# pwrseq_me14 register map
Registers are access not given, no defined reset value unless marked. A register's access mark holds for its fields unless they carry their own. Offsets are from the block's base; lines under a group give offsets from that group; [hi:lo] are bit positions; {n}, {i} and the like mark numbered series; 'fields as' and 'values as' point back to an identical list; <NAME> marks a mode.

## Memory map
0x40006800 PWRSEQ size 0x400 — Power Sequencer / Low Power Control Register.

## PWRSEQ — Power Sequencer / Low Power Control Register.
Base 0x40006800
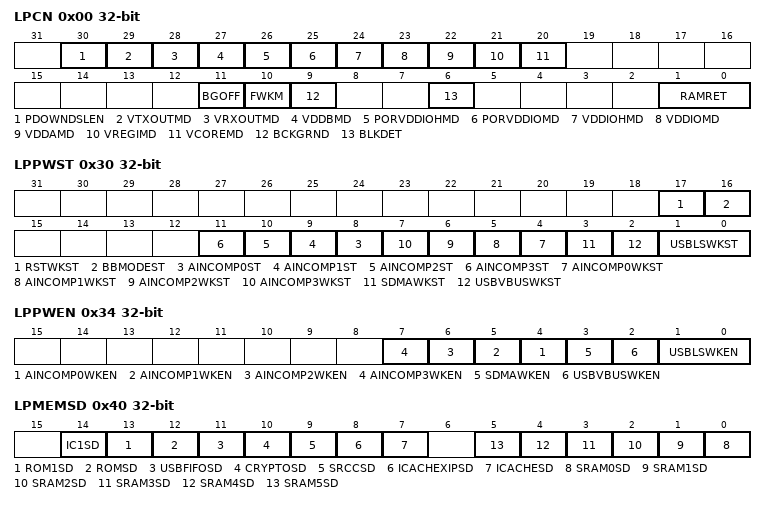
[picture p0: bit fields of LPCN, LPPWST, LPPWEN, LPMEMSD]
0x00 LPCN — Low Power Control Register.
  [30] PDOWNDSLEN — PDOWN DEEPSLEEP Output Enable .
  [29] VTXOUTMD — VTXOUT Bluetooth Transmitter Supply Power Monitor Disable .
  [28] VRXOUTMD — VRXOUT Bluetooth Receiver Supply Power Monitor Disable .
  [27] VDDBMD — VDDB Power-On Reset Monitor Disable. This bit controls the Power-On Reset monitor on VDDB supply in all operating mods.
    0=dis (Disabled.); 1=en (Enabled.)
  [26] PORVDDIOHMD — VDDIOH Power-On Reset Monitor Disable. This bit controls the Power-On Reset monitor on VDDIOH supply in all operating mods.
    0=dis (Disabled.); 1=en (Enabled.)
  [25] PORVDDIOMD — VDDIO Power-On Reset Monitor Disable. This bit controls the Power-On Reset monitor on VDDIO supply in all operating mods.
    0=dis (Disabled.); 1=en (Enabled.)
  [24] VDDIOHMD — VFDDIOH Monitor Disable. This bit controls the power monitor of the Analog Supply in all operating modes.
    0=en (Enable if Bandgap is ON(default)); 1=dis (Disabled.)
  [23] VDDIOMD — VDDIO Monitor Disable. This bit controls the power monitor of the Analog Supply in all operating modes.
    0=en (Enable if Bandgap is ON(default)); 1=dis (Disabled.)
  [22] VDDAMD — VDDA Monitor Disable. This bit controls the power monitor of the Analog Supply in all operating modes.
    0=en (Enable if Bandgap is ON(default)); 1=dis (Disabled.)
  [21] VREGIMD — VRTC Monitor Disable. This bit controls the power monitor on the Always-On Supply in all operating modes.
    0=en (Enable if Bandgap is ON(default)); 1=dis (Disabled.)
  [20] VCOREMD — VDDC(Vcore) Monitor Disable. This bit controls the power monitor on the VCore supply in all operating modes.
    0=en (Enable if Bandgap is ON(default)); 1=dis (Disabled.)
  [11] BGOFF — Bandgap OFF. This controls the System Bandgap in DeepSleep mode.
    0=on (Bandgap is always ON.); 1=off (Bandgap is OFF in DeepSleep mode(default).)
  [10] FWKM — Fast Wake-Up Mode. This bit enables fast wake-up from DeepSleep mode. (5uS typical).
    0=dis (Disabled.); 1=en (Enabled.)
  [9] BCKGRND — Background Mode ENable. This bit allows low-power background mode operations, while the CPU is in DeepSleep.
    0=dis (Disabled.); 1=en (Enabled.)
  [6] BLKDET — Block Auto-Detect
    0=enabled; 1=Disable
  [1:0] RAMRET — System RAM retention in BACKUP mode. These two bits are used in conjuction with RREGEN bit.
    0=dis (Disable Ram Retention.); 1=en1 (Enable System RAM 0 retention.); 2=en2 (Enable System RAM 0 and 1 retention.); 3=en3 (Enable System RAM 0 and 1 retention, if RREGEN=0, Enable all System RAM retention.)
0x04 LPWKST0 — Low Power I/O Wakeup Status Register 0. This register indicates the low power wakeup status for GPIO0.
  [31:0] WAKEST — Wakeup IRQ flags (write ones to clear). One or more of these bits will be set when the corresponding dedicated GPIO pin(s) transition(s) from low to high or high to low. If GPIO wakeup source is selected, using PM.GPIOWKEN register, and the corresponding bit is also selected in LPWKEN register, an interrupt will be gnerated to wake up the CPU from a low power mode.
0x08 LPWKEN0 — Low Power I/O Wakeup Enable Register 0. This register enables low power wakeup functionality for GPIO0.
  [30:0] WAKEEN — Enable wakeup. These bits allow wakeup from the corresponding GPIO pin(s) on transition(s) from low to high or high to low when PM.GPIOWKEN is set. Wakeup status is indicated in PPWKST register.
0x0C LPWKST1 — Low Power I/O Wakeup Status Register 1. This register indicates the low power wakeup status for GPIO1.
  [17:0] WAKEST — Wakeup IRQ flags (write ones to clear). One or more of these bits will be set when the corresponding dedicated GPIO pin(s) transition(s) from low to high or high to low. If GPIO wakeup source is selected, using PM.GPIOWKEN register, and the corresponding bit is also selected in LPWKEN register, an interrupt will be gnerated to wake up the CPU from a low power mode.
0x10 LPWKEN1 — Low Power I/O Wakeup Enable Register 1. This register enables low power wakeup functionality for GPIO1.
  fields as LPWKEN0
0x30 LPPWST — Low Power Peripheral Wakeup Status Register.
  [17] RSTWKST — Reset Detect Wakeup Status Flag.
  [16] BBMODEST — Battery Back Wakeup Flag (write one to clear). This bit will be set when exiting Battery Backup Mode.
  [n+8] AINCOMP{n}ST (n=0..3) — Analog Input Comparator {n} Output Status Flag.
  [n+4] AINCOMP{n}WKST (n=0..3) — Analog Input Comparator {n} Wakeup Status Flag.
  [3] SDMAWKST — Smart DMA Detect Wakeup Flag (write one to clear). This bit will be set when the SDMA IRQ transition from low to high or on high to low.
  [2] USBVBUSWKST — USB VBUS Detect Wakeup Flag (write one to clear). This bit will be set when the USB power supply is powered on or powered off.
  [1:0] USBLSWKST — USB UTMI Linestate Detect Wakeup Flag(write one to clear). One or both of these bits will be set when the USB bus activity causes the linestate to change and the device to wake while USB wakeup is enabled using PMLUSBWKEN.
0x34 LPPWEN — Low Power Peripheral Wakeup Enable Register.
  [n+4] AINCOMP{n}WKEN (n=0..3) — Analog Input Comparator {n} Wakeup Enable.
  [3] SDMAWKEN — Smart DMA Wakeup Enable. This bit allows wakeup from the Smart DMA IRQ.
  [2] USBVBUSWKEN — USB VBUS Detect Wakeup Enable. This bit allows wakeup from the USB power supply on or off status.
  [1:0] USBLSWKEN — USB UTMI Linestate Detect Wakeup Enable. These bits allow wakeup from the corresponding USB linestate signal(s) on transition(s) from low to high or high to low when PM.USBWKEN is set.
0x40 LPMEMSD — Low Power Memory Shutdown Control.
  [all] fields
    0=Normal Operating Mode; 1=Shutdown Mode
  [14] IC1SD — ICache 1 Shut Down.
  [13] ROM1SD — ROM1 Shut Down.
  [12] ROMSD — ROM Shut Down.
  [11] USBFIFOSD — USB FIFO Shut Down.
  [10] CRYPTOSD — Crypto MAA RAM Shut Down.
  [9] SRCCSD — System Cache RAM Shut Down.
  [8] ICACHEXIPSD — XiP Instruction Cache RAM Shut Down.
  [7] ICACHESD — Instruction Cache RAM Shut Down.
  [n] SRAM{n}SD (n=0..5) — System RAM block {n} Shut Down.
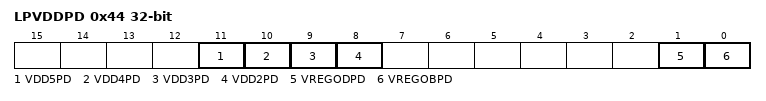
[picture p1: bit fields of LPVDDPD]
0x44 LPVDDPD — Low Power VDD Domain Power Down Control.
  [11] VDD5PD — Power down VDD5 (BTLE digital).
    0=up (Enabled); 1=down (Disabled)
  [10] VDD4PD — Power down VDD4 (SDMA+peripherals).
    0=up (Enabled); 1=down (Disabled)
  [9] VDD3PD — Power down VDD3 (CPU1+audio).
    0=up (Enabled); 1=down (Disabled)
  [8] VDD2PD — Power down VDD2 (CPU0+peripherals).
    0=up (Enabled); 1=down (Disabled)
  [1] VREGODPD — Power down SIMO Vreg D (BTLE).
    0=up (Enabled); 1=down (Disabled)
  [0] VREGOBPD — Power down SIMO Vreg B (VCOREB+VDDC) in backup mode.
    0=up (Enabled in backup mode.); 1=down (Disabled in backup mode.)
0x48 BURETVEC — General Purpose Register 0
0x4C BUAOD — General Purpose Register 1
